# NAVSS0_PROXY_0_ALIAS64K_PROXY0_SRC_TARGET0_DATA register map
Vendor: Texas Instruments
Peripheral module from a debugger description file (folder J721S2).
Registers are 32-bit, read-write, reset 0x0 unless marked. A register's access mark holds for its fields unless they carry their own. Offsets are as the file gives them; lines under a group give offsets from that group; [hi:lo] are bit positions; {n}, {i} and the like mark numbered series; 'fields as' and 'values as' point back to an identical list; <NAME> marks a mode.

## NAVSS0_PROXY_0_ALIAS64K_PROXY0_SRC_TARGET0_DATA
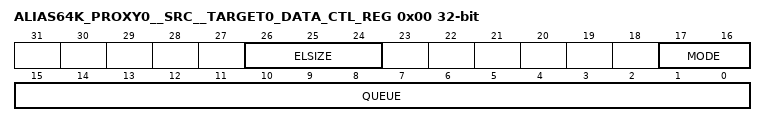
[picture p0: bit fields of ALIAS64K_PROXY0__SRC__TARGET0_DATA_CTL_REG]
0x00 ALIAS64K_PROXY0__SRC__TARGET0_DATA_CTL_REG — The Proxy Control for the proxy
  [26:24] ELSIZE — Queue element size. This field is encoded as follows: 0 = 4 bytes 1 = 8 bytes 2 = 16 bytes 3 = 32 bytes 4 = 64 bytes 5 = 128 bytes 6 = 256 bytes 7 = 512 bytes
  [17:16] MODE — Proxy Queue Mode that determines how to access the queue.
  [15:0] QUEUE — Proxy Queue
0x04 ALIAS64K_PROXY0__SRC__TARGET0_DATA_ST_REG — The Proxy Status for the proxy
  [31] ERROR — Proxy Error status
0x200 ALIAS64K_PROXY0__SRC__TARGET0_DATA_DATA_REG — The Proxy Data for the proxy, target and channel
  [31:0] DATA — Proxy Data
